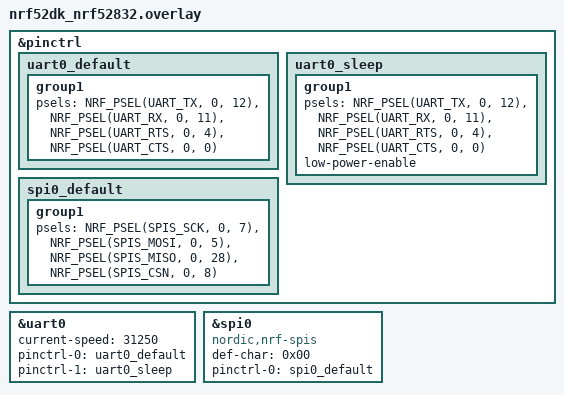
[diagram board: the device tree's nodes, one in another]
&pinctrl {

	uart0_default: uart0_default {
		group1 {
			psels = <NRF_PSEL(UART_TX, 0, 12)>,
				<NRF_PSEL(UART_RX, 0, 11)>,
				<NRF_PSEL(UART_RTS, 0, 4)>,
				<NRF_PSEL(UART_CTS, 0, 0)>;
		};
	};

	uart0_sleep: uart0_sleep {
		group1 {
			psels = <NRF_PSEL(UART_TX, 0, 12)>,
				<NRF_PSEL(UART_RX, 0, 11)>,
				<NRF_PSEL(UART_RTS, 0, 4)>,
				<NRF_PSEL(UART_CTS, 0, 0)>;
			low-power-enable;
		};
	};

	spi0_default: spi0_default {
		group1 {
			psels = <NRF_PSEL(SPIS_SCK, 0, 7)>,
				<NRF_PSEL(SPIS_MOSI, 0, 5)>,
				<NRF_PSEL(SPIS_MISO, 0, 28)>,
				<NRF_PSEL(SPIS_CSN, 0, 8)>;
		};
	};
};

&uart0 {
	current-speed = <31250>;
    pinctrl-0 = <&uart0_default>;
	pinctrl-1 = <&uart0_sleep>;
};

&spi0{
	status = "okay";
	compatible = "nordic,nrf-spis";
	def-char = <0x00>;
	pinctrl-0 = <&spi0_default>;
};
